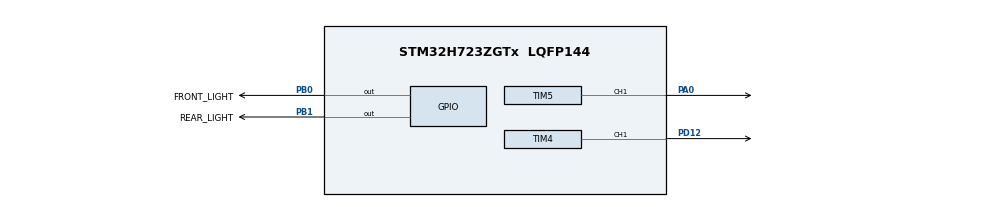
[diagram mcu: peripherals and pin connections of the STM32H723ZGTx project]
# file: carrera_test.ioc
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Mcu.Family=STM32H7
Mcu.Name=STM32H723ZGTx
Mcu.Package=LQFP144
NVIC.PriorityGroup=NVIC_PRIORITYGROUP_4
PA0.Signal=S_TIM5_CH1
PA13(JTMS/SWDIO).Mode=Trace_Asynchronous_SW
PA13(JTMS/SWDIO).Signal=DEBUG_JTMS-SWDIO
PA14(JTCK/SWCLK).Mode=Trace_Asynchronous_SW
PA14(JTCK/SWCLK).Signal=DEBUG_JTCK-SWCLK
PB0.GPIO_Label=FRONT_LIGHT
PB0.Signal=GPIO_Output
PB1.GPIO_Label=REAR_LIGHT
PB1.Signal=GPIO_Output
PB3(JTDO/TRACESWO).Mode=Trace_Asynchronous_SW
PB3(JTDO/TRACESWO).Signal=DEBUG_JTDO-SWO
PD12.Signal=S_TIM4_CH1
PH0-OSC_IN.Mode=HSE-External-Oscillator
PH0-OSC_IN.Signal=RCC_OSC_IN
PH1-OSC_OUT.Mode=HSE-External-Oscillator
PH1-OSC_OUT.Signal=RCC_OSC_OUT
ProjectManager.HeapSize=0x200
ProjectManager.StackSize=0x400
ProjectManager.TargetToolchain=STM32CubeIDE
RCC.ADCFreq_Value=129000000
RCC.APB1Freq_Value=64000000
RCC.APB2Freq_Value=64000000
RCC.APB3Freq_Value=64000000
RCC.APB4Freq_Value=64000000
RCC.CortexFreq_Value=64000000
RCC.HCLKFreq_Value=64000000
RCC.SYSCLKFreq_VALUE=64000000
RCC.USBFreq_Value=129000000
SH.S_TIM4_CH1.0=TIM4_CH1,PWM Generation1 CH1
SH.S_TIM5_CH1.0=TIM5_CH1,PWM Generation1 CH1
TIM4.Channel-PWM\ Generation1\ CH1=TIM_CHANNEL_1
TIM5.Channel-PWM\ Generation1\ CH1=TIM_CHANNEL_1
board=custom

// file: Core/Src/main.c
/* USER CODE BEGIN Header */
/**
  ******************************************************************************
  * @file           : main.c
  * @brief          : Main program body
  ******************************************************************************
  * @attention
  *
  * Copyright (c) 2024 STMicroelectronics.
  * All rights reserved.
  *
  * This software is licensed under terms that can be found in the LICENSE file
  * in the root directory of this software component.
  * If no LICENSE file comes with this software, it is provided AS-IS.
  *
  ******************************************************************************
  */
/* USER CODE END Header */
#include "main.h"

TIM_HandleTypeDef htim4;
TIM_HandleTypeDef htim5;

void SystemClock_Config(void);
static void MX_GPIO_Init(void);
static void MX_TIM4_Init(void);
static void MX_TIM5_Init(void);
/* USER CODE BEGIN PFP */
void mainInit();
void mainProcces();

/* USER CODE END PFP */

int main(void)
{

  /* MCU Configuration--------------------------------------------------------*/

  /* Reset of all peripherals, Initializes the Flash interface and the Systick. */
  HAL_Init();

  /* Configure the system clock */
  SystemClock_Config();

  /* Initialize all configured peripherals */
  MX_GPIO_Init();
  MX_TIM4_Init();
  MX_TIM5_Init();
  /* USER CODE BEGIN 2 */
  mainInit();

  /* USER CODE END 2 */

  /* Infinite loop */
  /* USER CODE BEGIN WHILE */
  while (1)
  {
	  mainProcces();
    /* USER CODE END WHILE */

  }
}

void SystemClock_Config(void)
{
  RCC_OscInitTypeDef RCC_OscInitStruct = {0};
  RCC_ClkInitTypeDef RCC_ClkInitStruct = {0};

  /** Supply configuration update enable
  */
  HAL_PWREx_ConfigSupply(PWR_LDO_SUPPLY);

  /** Configure the main internal regulator output voltage
  */
  __HAL_PWR_VOLTAGESCALING_CONFIG(PWR_REGULATOR_VOLTAGE_SCALE3);

  while(!__HAL_PWR_GET_FLAG(PWR_FLAG_VOSRDY)) {}

  /** Initializes the RCC Oscillators according to the specified parameters
  * in the RCC_OscInitTypeDef structure.
  */
  RCC_OscInitStruct.OscillatorType = RCC_OSCILLATORTYPE_HSI;
  RCC_OscInitStruct.HSIState = RCC_HSI_DIV1;
  RCC_OscInitStruct.HSICalibrationValue = 64;
  RCC_OscInitStruct.PLL.PLLState = RCC_PLL_NONE;
  if (HAL_RCC_OscConfig(&RCC_OscInitStruct) != HAL_OK)
  {
    Error_Handler();
  }

  /** Initializes the CPU, AHB and APB buses clocks
  */
  RCC_ClkInitStruct.ClockType = RCC_CLOCKTYPE_HCLK|RCC_CLOCKTYPE_SYSCLK
                              |RCC_CLOCKTYPE_PCLK1|RCC_CLOCKTYPE_PCLK2
                              |RCC_CLOCKTYPE_D3PCLK1|RCC_CLOCKTYPE_D1PCLK1;
  RCC_ClkInitStruct.SYSCLKSource = RCC_SYSCLKSOURCE_HSI;
  RCC_ClkInitStruct.SYSCLKDivider = RCC_SYSCLK_DIV1;
  RCC_ClkInitStruct.AHBCLKDivider = RCC_HCLK_DIV1;
  RCC_ClkInitStruct.APB3CLKDivider = RCC_APB3_DIV1;
  RCC_ClkInitStruct.APB1CLKDivider = RCC_APB1_DIV1;
  RCC_ClkInitStruct.APB2CLKDivider = RCC_APB2_DIV1;
  RCC_ClkInitStruct.APB4CLKDivider = RCC_APB4_DIV1;

  if (HAL_RCC_ClockConfig(&RCC_ClkInitStruct, FLASH_LATENCY_1) != HAL_OK)
  {
    Error_Handler();
  }
}

static void MX_TIM4_Init(void)
{

  TIM_MasterConfigTypeDef sMasterConfig = {0};
  TIM_OC_InitTypeDef sConfigOC = {0};

  htim4.Instance = TIM4;
  htim4.Init.Prescaler = 0;
  htim4.Init.CounterMode = TIM_COUNTERMODE_UP;
  htim4.Init.Period = 65535;
  htim4.Init.ClockDivision = TIM_CLOCKDIVISION_DIV1;
  htim4.Init.AutoReloadPreload = TIM_AUTORELOAD_PRELOAD_DISABLE;
  if (HAL_TIM_PWM_Init(&htim4) != HAL_OK)
  {
    Error_Handler();
  }
  sMasterConfig.MasterOutputTrigger = TIM_TRGO_RESET;
  sMasterConfig.MasterSlaveMode = TIM_MASTERSLAVEMODE_DISABLE;
  if (HAL_TIMEx_MasterConfigSynchronization(&htim4, &sMasterConfig) != HAL_OK)
  {
    Error_Handler();
  }
  sConfigOC.OCMode = TIM_OCMODE_PWM1;
  sConfigOC.Pulse = 0;
  sConfigOC.OCPolarity = TIM_OCPOLARITY_HIGH;
  sConfigOC.OCFastMode = TIM_OCFAST_DISABLE;
  if (HAL_TIM_PWM_ConfigChannel(&htim4, &sConfigOC, TIM_CHANNEL_1) != HAL_OK)
  {
    Error_Handler();
  }
  HAL_TIM_MspPostInit(&htim4);

}

static void MX_TIM5_Init(void)
{

  TIM_MasterConfigTypeDef sMasterConfig = {0};
  TIM_OC_InitTypeDef sConfigOC = {0};

  htim5.Instance = TIM5;
  htim5.Init.Prescaler = 0;
  htim5.Init.CounterMode = TIM_COUNTERMODE_UP;
  htim5.Init.Period = 4294967295;
  htim5.Init.ClockDivision = TIM_CLOCKDIVISION_DIV1;
  htim5.Init.AutoReloadPreload = TIM_AUTORELOAD_PRELOAD_DISABLE;
  if (HAL_TIM_PWM_Init(&htim5) != HAL_OK)
  {
    Error_Handler();
  }
  sMasterConfig.MasterOutputTrigger = TIM_TRGO_RESET;
  sMasterConfig.MasterSlaveMode = TIM_MASTERSLAVEMODE_DISABLE;
  if (HAL_TIMEx_MasterConfigSynchronization(&htim5, &sMasterConfig) != HAL_OK)
  {
    Error_Handler();
  }
  sConfigOC.OCMode = TIM_OCMODE_PWM1;
  sConfigOC.Pulse = 0;
  sConfigOC.OCPolarity = TIM_OCPOLARITY_HIGH;
  sConfigOC.OCFastMode = TIM_OCFAST_DISABLE;
  if (HAL_TIM_PWM_ConfigChannel(&htim5, &sConfigOC, TIM_CHANNEL_1) != HAL_OK)
  {
    Error_Handler();
  }
  HAL_TIM_MspPostInit(&htim5);

}

static void MX_GPIO_Init(void)
{
  GPIO_InitTypeDef GPIO_InitStruct = {0};

  /* GPIO Ports Clock Enable */
  __HAL_RCC_GPIOH_CLK_ENABLE();
  __HAL_RCC_GPIOA_CLK_ENABLE();
  __HAL_RCC_GPIOB_CLK_ENABLE();
  __HAL_RCC_GPIOD_CLK_ENABLE();

  /*Configure GPIO pin Output Level */
  HAL_GPIO_WritePin(GPIOB, FRONT_LIGHT_Pin|REAR_LIGHT_Pin, GPIO_PIN_RESET);

  /*Configure GPIO pins : FRONT_LIGHT_Pin REAR_LIGHT_Pin */
  GPIO_InitStruct.Pin = FRONT_LIGHT_Pin|REAR_LIGHT_Pin;
  GPIO_InitStruct.Mode = GPIO_MODE_OUTPUT_PP;
  GPIO_InitStruct.Pull = GPIO_NOPULL;
  GPIO_InitStruct.Speed = GPIO_SPEED_FREQ_LOW;
  HAL_GPIO_Init(GPIOB, &GPIO_InitStruct);

}

void Error_Handler(void)
{
  __disable_irq();
  while (1)
  {
  }
}
